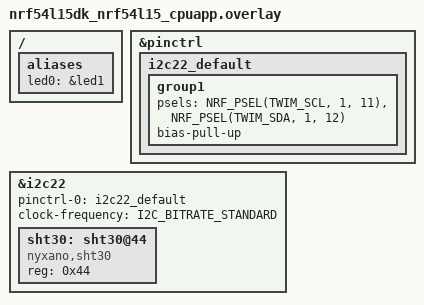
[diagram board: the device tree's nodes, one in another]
/ { aliases { led0 = &led1; }; };

&pinctrl {
    i2c22_default: i2c22_default {
        group1 {
            psels = <NRF_PSEL(TWIM_SCL, 1, 11)>,
                    <NRF_PSEL(TWIM_SDA, 1, 12)>;
            bias-pull-up;
        };
    };
};

&i2c22 {
    status = "okay";
    pinctrl-0 = <&i2c22_default>;
    pinctrl-names = "default";
    clock-frequency = <I2C_BITRATE_STANDARD>;

    sht30: sht30@44 {
        compatible = "nyxano,sht30";
        reg = <0x44>;
    };
};
